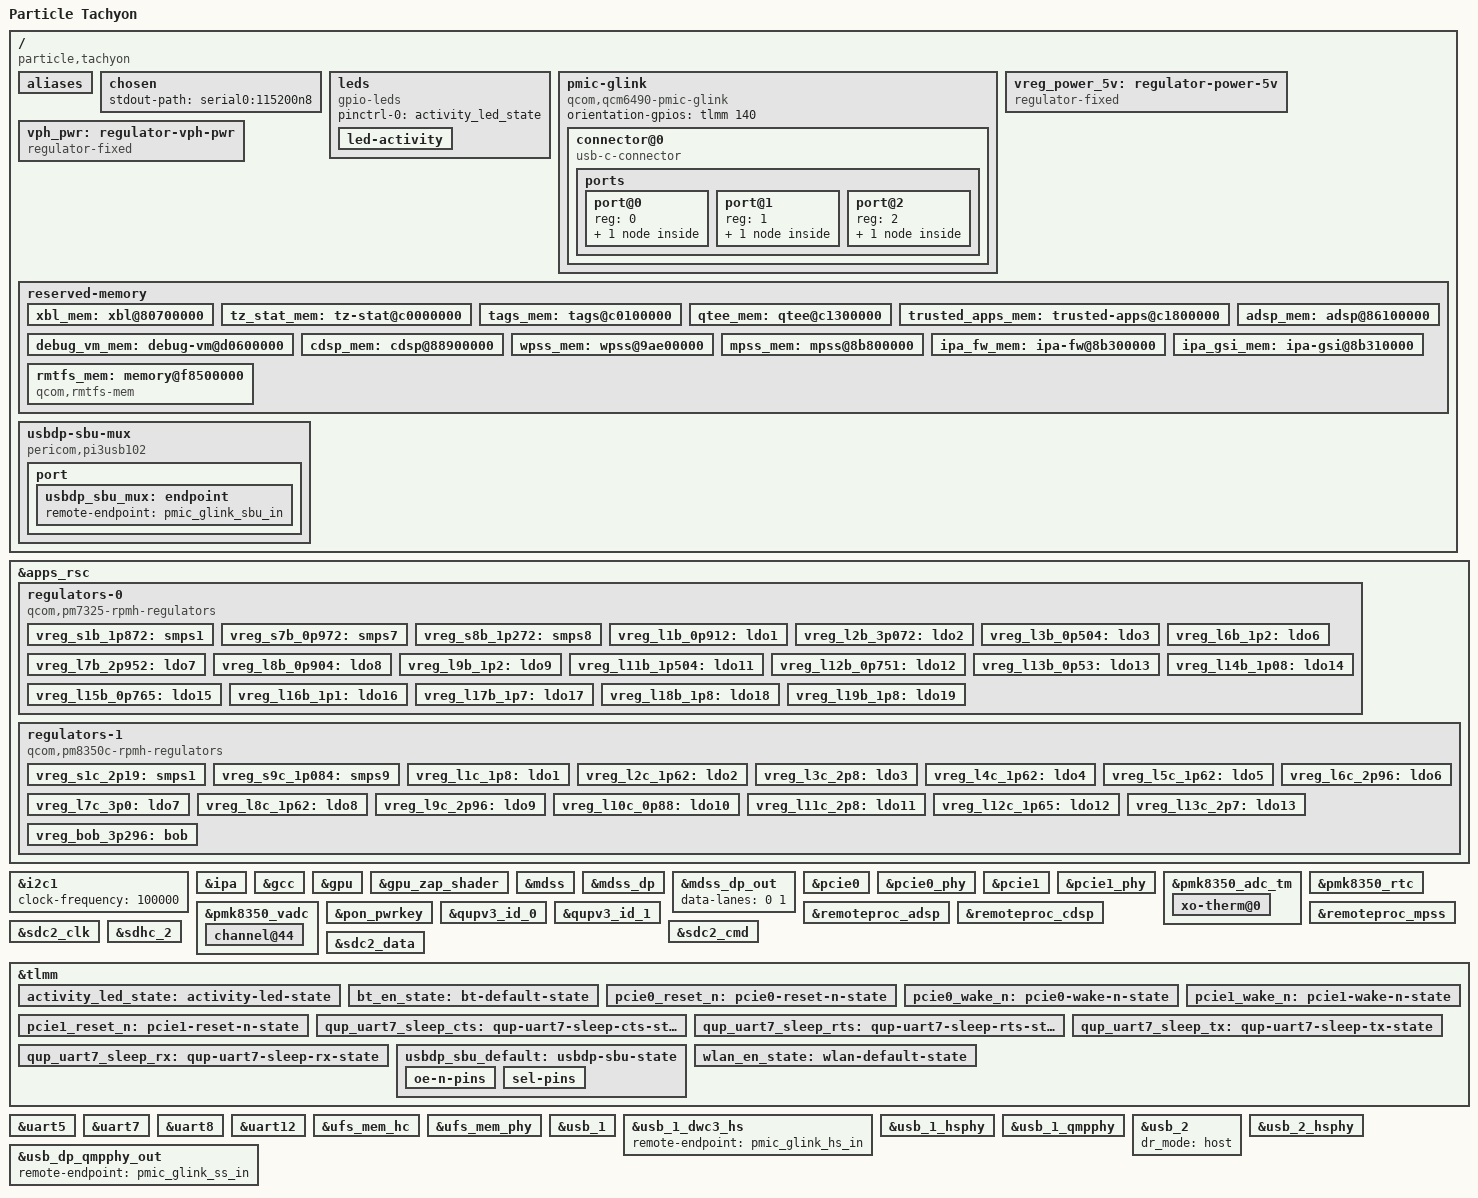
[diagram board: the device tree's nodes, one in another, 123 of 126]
// SPDX-License-Identifier: BSD-3-Clause
/*
 * Copyright (c) Qualcomm Technologies, Inc. and/or its subsidiaries.
 * Copyright (c) 2023, Luca Weiss <luca.weiss@fairphone.com>
 */

/dts-v1/;

#include <dt-bindings/iio/qcom,spmi-adc7-pmk8350.h>
#include <dt-bindings/iio/qcom,spmi-adc7-pm7325.h>
#include <dt-bindings/leds/common.h>
#include <dt-bindings/pinctrl/qcom,pmic-gpio.h>
#include <dt-bindings/regulator/qcom,rpmh-regulator.h>
#include "sc7280.dtsi"
#include "pm8350c.dtsi"
#include "pmk8350.dtsi"

/delete-node/ &ipa_fw_mem;
/delete-node/ &rmtfs_mem;
/delete-node/ &xbl_mem;
/delete-node/ &adsp_mem;
/delete-node/ &cdsp_mem;
/delete-node/ &wpss_mem;

/ {
	model = "Particle Tachyon";
	compatible = "particle,tachyon", "qcom,qcm6490";
	chassis-type = "embedded";

	aliases {
		serial0 = &uart5;
		serial1 = &uart12;
		serial2 = &uart7;
		serial3 = &uart8;
	};

	chosen {
		stdout-path = "serial0:115200n8";
	};

	leds {
		compatible = "gpio-leds";

		pinctrl-0 = <&activity_led_state>;
		pinctrl-names = "default";

		led-activity {
			function = LED_FUNCTION_ACTIVITY;
			color = <LED_COLOR_ID_RED>;
			gpios = <&tlmm 14 GPIO_ACTIVE_HIGH>;
			default-state = "on";
			panic-indicator;
		};
	};

	pmic-glink {
		compatible = "qcom,qcm6490-pmic-glink", "qcom,pmic-glink";

		#address-cells = <1>;
		#size-cells = <0>;
		orientation-gpios = <&tlmm 140 GPIO_ACTIVE_HIGH>;

		connector@0 {
			compatible = "usb-c-connector";
			reg = <0>;
			power-role = "dual";
			data-role = "dual";

			ports {
				#address-cells = <1>;
				#size-cells = <0>;

				port@0 {
					reg = <0>;

					pmic_glink_hs_in: endpoint {
						remote-endpoint = <&usb_1_dwc3_hs>;
					};
				};

				port@1 {
					reg = <1>;

					pmic_glink_ss_in: endpoint {
						remote-endpoint = <&usb_dp_qmpphy_out>;
					};
				};

				port@2 {
					reg = <2>;

					pmic_glink_sbu_in: endpoint {
						remote-endpoint = <&usbdp_sbu_mux>;
					};
				};
			};
		};
	};

	vreg_power_5v: regulator-power-5v {
		compatible = "regulator-fixed";
		regulator-name = "power_5v";
		regulator-min-microvolt = <5000000>;
		regulator-max-microvolt = <5000000>;
		gpio = <&tlmm 13 GPIO_ACTIVE_HIGH>;
		enable-active-high;
	};

	vph_pwr: regulator-vph-pwr {
		compatible = "regulator-fixed";
		regulator-name = "vph_pwr";
		regulator-min-microvolt = <3700000>;
		regulator-max-microvolt = <3700000>;
	};

	reserved-memory {
		xbl_mem: xbl@80700000 {
			reg = <0x0 0x80700000 0x0 0x100000>;
			no-map;
		};

		tz_stat_mem: tz-stat@c0000000 {
			reg = <0x0 0xc0000000 0x0 0x100000>;
			no-map;
		};

		tags_mem: tags@c0100000 {
			reg = <0x0 0xc0100000 0x0 0x1200000>;
			no-map;
		};

		qtee_mem: qtee@c1300000 {
			reg = <0x0 0xc1300000 0x0 0x500000>;
			no-map;
		};

		trusted_apps_mem: trusted-apps@c1800000 {
			reg = <0x0 0xc1800000 0x0 0x1c00000>;
			no-map;
		};

		debug_vm_mem: debug-vm@d0600000 {
			reg = <0x0 0xd0600000 0x0 0x100000>;
			no-map;
		};

		adsp_mem: adsp@86100000 {
			reg = <0x0 0x86700000 0x0 0x2800000>;
			no-map;
		};

		cdsp_mem: cdsp@88900000 {
			reg = <0x0 0x88f00000 0x0 0x1e00000>;
			no-map;
		};

		wpss_mem: wpss@9ae00000 {
			reg = <0x0 0x9ae00000 0x0 0x1900000>;
			no-map;
		};

		mpss_mem: mpss@8b800000 {
			reg = <0x0 0x8b800000 0x0 0xf600000>;
			no-map;
		};

		ipa_fw_mem: ipa-fw@8b300000 {
			reg = <0x0 0x8b700000 0x0 0x10000>;
			no-map;
		};

		ipa_gsi_mem: ipa-gsi@8b310000 {
			reg = <0x0 0x8b710000 0x0 0xa000>;
			no-map;
		};

		rmtfs_mem: memory@f8500000 {
			compatible = "qcom,rmtfs-mem";
			reg = <0x0 0xf8500000 0x0 0x600000>;
			no-map;

			qcom,client-id = <1>;
			qcom,vmid = <QCOM_SCM_VMID_MSS_MSA>, <QCOM_SCM_VMID_NAV>;
		};
	};


	usbdp-sbu-mux {
		compatible = "pericom,pi3usb102", "gpio-sbu-mux";

		enable-gpios = <&tlmm 108 GPIO_ACTIVE_HIGH>;
		select-gpios = <&tlmm 42 GPIO_ACTIVE_HIGH>;

		pinctrl-0 = <&usbdp_sbu_default>;
		pinctrl-names = "default";

		mode-switch;
		orientation-switch;

		port {
			usbdp_sbu_mux: endpoint {
				remote-endpoint = <&pmic_glink_sbu_in>;
			};
		};
	};
};

&apps_rsc {
	regulators-0 {
		compatible = "qcom,pm7325-rpmh-regulators";
		qcom,pmic-id = "b";

		vdd-s1-supply = <&vph_pwr>;
		vdd-s2-supply = <&vph_pwr>;
		vdd-s3-supply = <&vph_pwr>;
		vdd-s4-supply = <&vph_pwr>;
		vdd-s5-supply = <&vph_pwr>;
		vdd-s6-supply = <&vph_pwr>;
		vdd-s7-supply = <&vph_pwr>;
		vdd-s8-supply = <&vph_pwr>;
		vdd-l1-l4-l12-l15-supply = <&vreg_s7b_0p972>;
		vdd-l2-l7-supply = <&vreg_bob_3p296>;
		vdd-l6-l9-l10-supply = <&vreg_s8b_1p272>;
		vdd-l8-supply = <&vreg_s7b_0p972>;
		vdd-l11-l17-l18-l19-supply = <&vreg_s1b_1p872>;
		vdd-l13-supply = <&vreg_s7b_0p972>;
		vdd-l14-l16-supply = <&vreg_s8b_1p272>;

		vreg_s1b_1p872: smps1 {
			regulator-name = "vreg_s1b_1p872";
			regulator-min-microvolt = <1840000>;
			regulator-max-microvolt = <2040000>;
		};

		vreg_s7b_0p972: smps7 {
			regulator-name = "vreg_s7b_0p972";
			regulator-min-microvolt = <535000>;
			regulator-max-microvolt = <1120000>;
		};

		vreg_s8b_1p272: smps8 {
			regulator-name = "vreg_s8b_1p272";
			regulator-min-microvolt = <1200000>;
			regulator-max-microvolt = <1500000>;
			regulator-initial-mode = <RPMH_REGULATOR_MODE_RET>;
		};

		vreg_l1b_0p912: ldo1 {
			regulator-name = "vreg_l1b_0p912";
			regulator-min-microvolt = <825000>;
			regulator-max-microvolt = <925000>;
			regulator-initial-mode = <RPMH_REGULATOR_MODE_HPM>;
		};

		vreg_l2b_3p072: ldo2 {
			regulator-name = "vreg_l2b_3p072";
			regulator-min-microvolt = <2700000>;
			regulator-max-microvolt = <3544000>;
			regulator-initial-mode = <RPMH_REGULATOR_MODE_HPM>;
		};

		vreg_l3b_0p504: ldo3 {
			regulator-name = "vreg_l3b_0p504";
			regulator-min-microvolt = <312000>;
			regulator-max-microvolt = <910000>;
			regulator-initial-mode = <RPMH_REGULATOR_MODE_HPM>;
		};

		vreg_l6b_1p2: ldo6 {
			regulator-name = "vreg_l6b_1p2";
			regulator-min-microvolt = <1140000>;
			regulator-max-microvolt = <1260000>;
			regulator-initial-mode = <RPMH_REGULATOR_MODE_HPM>;
		};

		vreg_l7b_2p952: ldo7 {
			regulator-name = "vreg_l7b_2p952";
			regulator-min-microvolt = <2952000>;
			regulator-max-microvolt = <2952000>;
			regulator-initial-mode = <RPMH_REGULATOR_MODE_HPM>;
		};

		vreg_l8b_0p904: ldo8 {
			regulator-name = "vreg_l8b_0p904";
			regulator-min-microvolt = <870000>;
			regulator-max-microvolt = <970000>;
			regulator-initial-mode = <RPMH_REGULATOR_MODE_HPM>;
		};

		vreg_l9b_1p2: ldo9 {
			regulator-name = "vreg_l9b_1p2";
			regulator-min-microvolt = <1200000>;
			regulator-max-microvolt = <1200000>;
			regulator-initial-mode = <RPMH_REGULATOR_MODE_HPM>;
			regulator-allow-set-load;
			regulator-allowed-modes = <RPMH_REGULATOR_MODE_LPM
						   RPMH_REGULATOR_MODE_HPM>;
		};

		vreg_l11b_1p504: ldo11 {
			regulator-name = "vreg_l11b_1p504";
			regulator-min-microvolt = <1504000>;
			regulator-max-microvolt = <2000000>;
			regulator-initial-mode = <RPMH_REGULATOR_MODE_HPM>;
		};

		vreg_l12b_0p751: ldo12 {
			regulator-name = "vreg_l12b_0p751";
			regulator-min-microvolt = <751000>;
			regulator-max-microvolt = <824000>;
			regulator-initial-mode = <RPMH_REGULATOR_MODE_HPM>;
		};

		vreg_l13b_0p53: ldo13 {
			regulator-name = "vreg_l13b_0p53";
			regulator-min-microvolt = <530000>;
			regulator-max-microvolt = <824000>;
			regulator-initial-mode = <RPMH_REGULATOR_MODE_HPM>;
		};

		vreg_l14b_1p08: ldo14 {
			regulator-name = "vreg_l14b_1p08";
			regulator-min-microvolt = <1080000>;
			regulator-max-microvolt = <1304000>;
			regulator-initial-mode = <RPMH_REGULATOR_MODE_HPM>;
		};

		vreg_l15b_0p765: ldo15 {
			regulator-name = "vreg_l15b_0p765";
			regulator-min-microvolt = <765000>;
			regulator-max-microvolt = <1020000>;
			regulator-initial-mode = <RPMH_REGULATOR_MODE_HPM>;
		};

		vreg_l16b_1p1: ldo16 {
			regulator-name = "vreg_l16b_1p1";
			regulator-min-microvolt = <1100000>;
			regulator-max-microvolt = <1300000>;
			regulator-initial-mode = <RPMH_REGULATOR_MODE_HPM>;
		};

		vreg_l17b_1p7: ldo17 {
			regulator-name = "vreg_l17b_1p7";
			regulator-min-microvolt = <1700000>;
			regulator-max-microvolt = <1900000>;
			regulator-initial-mode = <RPMH_REGULATOR_MODE_HPM>;
		};

		vreg_l18b_1p8: ldo18 {
			regulator-name = "vreg_l18b_1p8";
			regulator-min-microvolt = <1800000>;
			regulator-max-microvolt = <2000000>;
			regulator-initial-mode = <RPMH_REGULATOR_MODE_HPM>;
		};

		vreg_l19b_1p8: ldo19 {
			regulator-name = "vreg_l19b_1p8";
			regulator-min-microvolt = <1800000>;
			regulator-max-microvolt = <2000000>;
			regulator-initial-mode = <RPMH_REGULATOR_MODE_HPM>;
		};
	};

	regulators-1 {
		compatible = "qcom,pm8350c-rpmh-regulators";
		qcom,pmic-id = "c";

		vdd-s1-supply = <&vph_pwr>;
		vdd-s2-supply = <&vph_pwr>;
		vdd-s3-supply = <&vph_pwr>;
		vdd-s4-supply = <&vph_pwr>;
		vdd-s5-supply = <&vph_pwr>;
		vdd-s6-supply = <&vph_pwr>;
		vdd-s7-supply = <&vph_pwr>;
		vdd-s8-supply = <&vph_pwr>;
		vdd-s9-supply = <&vph_pwr>;
		vdd-s10-supply = <&vph_pwr>;
		vdd-l1-l12-supply = <&vreg_s1b_1p872>;
		vdd-l2-l8-supply = <&vreg_s1b_1p872>;
		vdd-l3-l4-l5-l7-l13-supply = <&vreg_bob_3p296>;
		vdd-l6-l9-l11-supply = <&vreg_bob_3p296>;
		vdd-l10-supply = <&vreg_s7b_0p972>;
		vdd-bob-supply = <&vph_pwr>;

		vreg_s1c_2p19: smps1 {
			regulator-name = "vreg_s1c_2p19";
			regulator-min-microvolt = <2190000>;
			regulator-max-microvolt = <2210000>;
		};

		vreg_s9c_1p084: smps9 {
			regulator-name = "vreg_s9c_1p084";
			regulator-min-microvolt = <1084000>;
			regulator-max-microvolt = <1170000>;
		};

		vreg_l1c_1p8: ldo1 {
			regulator-name = "vreg_l1c_1p8";
			regulator-min-microvolt = <1800000>;
			regulator-max-microvolt = <1980000>;
			regulator-initial-mode = <RPMH_REGULATOR_MODE_HPM>;
		};

		vreg_l2c_1p62: ldo2 {
			regulator-name = "vreg_l2c_1p62";
			regulator-min-microvolt = <1620000>;
			regulator-max-microvolt = <1980000>;
			regulator-initial-mode = <RPMH_REGULATOR_MODE_HPM>;
		};

		vreg_l3c_2p8: ldo3 {
			regulator-name = "vreg_l3c_2p8";
			regulator-min-microvolt = <2800000>;
			regulator-max-microvolt = <3540000>;
			regulator-initial-mode = <RPMH_REGULATOR_MODE_HPM>;
		};

		vreg_l4c_1p62: ldo4 {
			regulator-name = "vreg_l4c_1p62";
			regulator-min-microvolt = <1620000>;
			regulator-max-microvolt = <3300000>;
			regulator-initial-mode = <RPMH_REGULATOR_MODE_HPM>;
		};

		vreg_l5c_1p62: ldo5 {
			regulator-name = "vreg_l5c_1p62";
			regulator-min-microvolt = <1620000>;
			regulator-max-microvolt = <3300000>;
			regulator-initial-mode = <RPMH_REGULATOR_MODE_HPM>;
		};

		vreg_l6c_2p96: ldo6 {
			regulator-name = "vreg_l6c_2p96";
			regulator-min-microvolt = <1650000>;
			regulator-max-microvolt = <3544000>;
			regulator-initial-mode = <RPMH_REGULATOR_MODE_HPM>;
		};

		vreg_l7c_3p0: ldo7 {
			regulator-name = "vreg_l7c_3p0";
			regulator-min-microvolt = <3000000>;
			regulator-max-microvolt = <3544000>;
			regulator-initial-mode = <RPMH_REGULATOR_MODE_HPM>;
		};

		vreg_l8c_1p62: ldo8 {
			regulator-name = "vreg_l8c_1p62";
			regulator-min-microvolt = <1620000>;
			regulator-max-microvolt = <2000000>;
			regulator-initial-mode = <RPMH_REGULATOR_MODE_HPM>;
		};

		vreg_l9c_2p96: ldo9 {
			regulator-name = "vreg_l9c_2p96";
			regulator-min-microvolt = <2960000>;
			regulator-max-microvolt = <3544000>;
			regulator-initial-mode = <RPMH_REGULATOR_MODE_HPM>;
		};

		vreg_l10c_0p88: ldo10 {
			regulator-name = "vreg_l10c_0p88";
			regulator-min-microvolt = <720000>;
			regulator-max-microvolt = <1050000>;
			regulator-initial-mode = <RPMH_REGULATOR_MODE_HPM>;
		};

		vreg_l11c_2p8: ldo11 {
			regulator-name = "vreg_l11c_2p8";
			regulator-min-microvolt = <2800000>;
			regulator-max-microvolt = <3544000>;
			regulator-initial-mode = <RPMH_REGULATOR_MODE_HPM>;
		};

		vreg_l12c_1p65: ldo12 {
			regulator-name = "vreg_l12c_1p65";
			regulator-min-microvolt = <1650000>;
			regulator-max-microvolt = <2000000>;
			regulator-initial-mode = <RPMH_REGULATOR_MODE_HPM>;
		};

		vreg_l13c_2p7: ldo13 {
			regulator-name = "vreg_l13c_2p7";
			regulator-min-microvolt = <2700000>;
			regulator-max-microvolt = <3544000>;
			regulator-initial-mode = <RPMH_REGULATOR_MODE_HPM>;
		};

		vreg_bob_3p296: bob {
			regulator-name = "vreg_bob_3p296";
			regulator-min-microvolt = <3008000>;
			regulator-max-microvolt = <3960000>;
		};
	};
};

&i2c1 {
	clock-frequency = <100000>;

	status = "okay";
};

&ipa {
	firmware-name = "qcom/qcm6490/particle/tachyon/ipa_fws.mbn";
	qcom,gsi-loader = "self";
	memory-region = <&ipa_fw_mem>;

	status = "okay";
};

&gcc {
	protected-clocks = <GCC_CFG_NOC_LPASS_CLK>,
			   <GCC_MSS_CFG_AHB_CLK>,
			   <GCC_MSS_GPLL0_MAIN_DIV_CLK_SRC>,
			   <GCC_MSS_OFFLINE_AXI_CLK>,
			   <GCC_MSS_Q6SS_BOOT_CLK_SRC>,
			   <GCC_MSS_Q6_MEMNOC_AXI_CLK>,
			   <GCC_MSS_SNOC_AXI_CLK>,
			   <GCC_QSPI_CNOC_PERIPH_AHB_CLK>,
			   <GCC_QSPI_CORE_CLK>,
			   <GCC_QSPI_CORE_CLK_SRC>,
			   <GCC_SEC_CTRL_CLK_SRC>,
			   <GCC_WPSS_AHB_BDG_MST_CLK>,
			   <GCC_WPSS_AHB_CLK>,
			   <GCC_WPSS_RSCP_CLK>;
};

&gpu {
	status = "okay";
};

&gpu_zap_shader {
	firmware-name = "qcom/qcm6490/particle/tachyon/a660_zap.mbn";
};

&mdss {
	status = "okay";
};

&mdss_dp {
	status = "okay";
};

&mdss_dp_out {
	data-lanes = <0 1>;
};

&pcie0 {
	perst-gpios = <&tlmm 87 GPIO_ACTIVE_LOW>;
	wake-gpios = <&tlmm 89 GPIO_ACTIVE_HIGH>;

	pinctrl-0 = <&pcie0_reset_n>, <&pcie0_wake_n>, <&pcie0_clkreq_n>;
	pinctrl-names = "default";

	status = "okay";
};

&pcie0_phy {
	vdda-phy-supply = <&vreg_l10c_0p88>;
	vdda-pll-supply = <&vreg_l6b_1p2>;

	status = "okay";
};

&pcie1 {
	perst-gpios = <&tlmm 2 GPIO_ACTIVE_LOW>;

	pinctrl-0 = <&pcie1_reset_n>, <&pcie1_wake_n>, <&pcie1_clkreq_n>;
	pinctrl-names = "default";

	vddpe-3v3-supply = <&vreg_power_5v>;

	status = "okay";
};

&pcie1_phy {
	vdda-phy-supply = <&vreg_l10c_0p88>;
	vdda-pll-supply = <&vreg_l6b_1p2>;

	status = "okay";
};

&pmk8350_adc_tm {
	status = "okay";

	xo-therm@0 {
		reg = <0>;
		io-channels = <&pmk8350_vadc PMK8350_ADC7_AMUX_THM1_100K_PU>;
		qcom,ratiometric;
		qcom,hw-settle-time-us = <200>;
	};
};

&pmk8350_rtc {
	status = "okay";
};

&pmk8350_vadc {
	status = "okay";

	channel@44 {
		reg = <PMK8350_ADC7_AMUX_THM1_100K_PU>;
		qcom,ratiometric;
		qcom,hw-settle-time = <200>;
		qcom,pre-scaling = <1 1>;
		label = "pmk8350_xo_therm";
	};
};

&pon_pwrkey {
	status = "okay";
};

&qupv3_id_0 {
	status = "okay";
};

&qupv3_id_1 {
	status = "okay";
};

&remoteproc_adsp {
	firmware-name = "qcom/qcm6490/particle/tachyon/adsp.mbn";
	status = "okay";
};

&remoteproc_cdsp {
	firmware-name = "qcom/qcm6490/particle/tachyon/cdsp.mbn";
	status = "okay";
};

&remoteproc_mpss {
	firmware-name = "qcom/qcm6490/particle/tachyon/modem.mbn";
	status = "okay";
};

&sdc2_clk {
	bias-disable;
	drive-strength = <16>;
};

&sdc2_cmd {
	bias-pull-up;
	drive-strength = <10>;
};

&sdc2_data {
	bias-pull-up;
	drive-strength = <10>;
};

&sdhc_2 {
	vmmc-supply = <&vreg_l9c_2p96>;
	vqmmc-supply = <&vreg_l6c_2p96>;

	cd-gpios = <&tlmm 91 GPIO_ACTIVE_LOW>;

	status = "okay";
};

&tlmm {
	activity_led_state: activity-led-state {
		pins = "gpio14";
		function = "gpio";
		bias-disable;
	};

	bt_en_state: bt-default-state {
		pins = "gpio84";
		function = "gpio";
		drive-strength = <16>;
		output-low;
		bias-pull-up;
	};

	pcie0_reset_n: pcie0-reset-n-state {
		pins = "gpio87";
		function = "gpio";
		drive-strength = <16>;
		output-low;
		bias-disable;
	};

	pcie0_wake_n: pcie0-wake-n-state {
		pins = "gpio89";
		function = "gpio";
		drive-strength = <2>;
		bias-pull-up;
	};

	pcie1_reset_n: pcie1-reset-n-state {
		pins = "gpio2";
		function = "gpio";
		drive-strength = <16>;
		output-low;
		bias-disable;
	};

	pcie1_wake_n: pcie1-wake-n-state {
		pins = "gpio3";
		function = "gpio";
		drive-strength = <2>;
		bias-pull-up;
	};

	qup_uart7_sleep_cts: qup-uart7-sleep-cts-state {
		pins = "gpio28";
		function = "gpio";
		/*
		 * Configure a bias-bus-hold on CTS to lower power
		 * usage when Bluetooth is turned off. Bus hold will
		 * maintain a low power state regardless of whether
		 * the Bluetooth module drives the pin in either
		 * direction or leaves the pin fully unpowered.
		 */
		bias-bus-hold;
	};

	qup_uart7_sleep_rts: qup-uart7-sleep-rts-state {
		pins = "gpio29";
		function = "gpio";
		/*
		 * Configure pull-down on RTS. As RTS is active low
		 * signal, pull it low to indicate the BT SoC that it
		 * can wakeup the system anytime from suspend state by
		 * pulling RX low (by sending wakeup bytes).
		 */
		bias-pull-down;
	};

	qup_uart7_sleep_tx: qup-uart7-sleep-tx-state {
		pins = "gpio30";
		function = "gpio";
		/*
		 * Configure pull-up on TX when it isn't actively driven
		 * to prevent BT SoC from receiving garbage during sleep.
		 */
		bias-pull-up;
	};

	qup_uart7_sleep_rx: qup-uart7-sleep-rx-state {
		pins = "gpio31";
		function = "gpio";
		/*
		 * Configure a pull-up on RX. This is needed to avoid
		 * garbage data when the TX pin of the Bluetooth module
		 * is floating which may cause spurious wakeups.
		 */
		bias-pull-up;
	};

	usbdp_sbu_default: usbdp-sbu-state {
		oe-n-pins {
			pins = "gpio108";
			function = "gpio";
			bias-disable;
			drive-strength = <16>;
			output-high;
		};

		sel-pins {
			pins = "gpio42";
			function = "gpio";
			bias-disable;
			drive-strength = <16>;
		};
	};

	wlan_en_state: wlan-default-state {
		pins = "gpio85";
		function = "gpio";
		drive-strength = <16>;
		output-low;
		bias-pull-up;
	};
};

&uart5 {
	status = "okay";
};

&uart7 {
	/delete-property/ interrupts;
	interrupts-extended = <&intc GIC_SPI 608 IRQ_TYPE_LEVEL_HIGH>,
			      <&tlmm 31 IRQ_TYPE_EDGE_FALLING>;

	pinctrl-1 = <&qup_uart7_sleep_cts>,
		    <&qup_uart7_sleep_rts>,
		    <&qup_uart7_sleep_tx>,
		    <&qup_uart7_sleep_rx>;
	pinctrl-names = "default", "sleep";

	status = "okay";
};

&uart8 {
	status = "okay";
};

&uart12 {
	status = "okay";
};

&ufs_mem_hc {
	reset-gpios = <&tlmm 175 GPIO_ACTIVE_LOW>;
	vcc-supply = <&vreg_l7b_2p952>;
	vcc-max-microamp = <800000>;
	vccq-supply = <&vreg_l9b_1p2>;
	vccq-max-microamp = <900000>;
	vccq2-supply = <&vreg_l9b_1p2>;
	vccq2-max-microamp = <900000>;

	status = "okay";
};

&ufs_mem_phy {
	vdda-phy-supply = <&vreg_l10c_0p88>;
	vdda-pll-supply = <&vreg_l6b_1p2>;

	status = "okay";
};

&usb_1 {
	dr_mode = "otg";
	usb-role-switch;

	status = "okay";
};

&usb_1_dwc3_hs {
	remote-endpoint = <&pmic_glink_hs_in>;
};

&usb_1_hsphy {
	vdda-pll-supply = <&vreg_l10c_0p88>;
	vdda33-supply = <&vreg_l2b_3p072>;
	vdda18-supply = <&vreg_l1c_1p8>;

	status = "okay";
};

&usb_1_qmpphy {
	vdda-phy-supply = <&vreg_l6b_1p2>;
	vdda-pll-supply = <&vreg_l1b_0p912>;

	status = "okay";
};

&usb_2 {
	dr_mode = "host";

	status = "okay";
};

&usb_2_hsphy {
	vdda-pll-supply = <&vreg_l10c_0p88>;
	vdda18-supply = <&vreg_l1c_1p8>;
	vdda33-supply = <&vreg_l2b_3p072>;

	status = "okay";
};

&usb_dp_qmpphy_out {
	remote-endpoint = <&pmic_glink_ss_in>;
};
